VERSION "haltech-v2.35.0-subset"

NS_ :

BS_:

BU_: ECU GAUGES

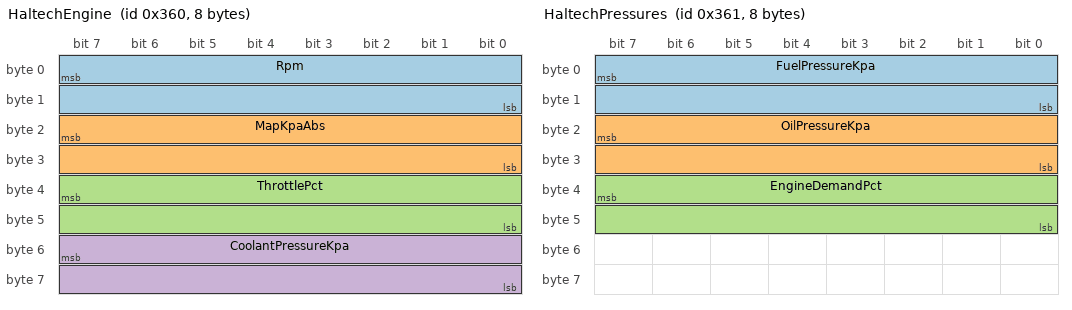
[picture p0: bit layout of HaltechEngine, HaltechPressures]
BO_ 864 HaltechEngine: 8 ECU
 SG_ Rpm : 7|16@0+ (1.0,0.0) [0.0|20000.0] "rpm" GAUGES
 SG_ MapKpaAbs : 23|16@0+ (0.1,0.0) [0.0|1000.0] "kPa" GAUGES
 SG_ ThrottlePct : 39|16@0+ (0.1,0.0) [0.0|100.0] "%" GAUGES
 SG_ CoolantPressureKpa : 55|16@0+ (0.1,-101.3) [-101.3|1000.0] "kPa" GAUGES

BO_ 865 HaltechPressures: 8 ECU
 SG_ FuelPressureKpa : 7|16@0+ (0.1,-101.3) [-101.3|1000.0] "kPa" GAUGES
 SG_ OilPressureKpa : 23|16@0+ (0.1,-101.3) [-101.3|1000.0] "kPa" GAUGES
 SG_ EngineDemandPct : 39|16@0+ (0.1,0.0) [0.0|400.0] "%" GAUGES

BO_ 880 HaltechSpeed: 8 ECU
 SG_ VehicleSpeedKph : 7|16@0+ (0.1,0.0) [0.0|400.0] "km/h" GAUGES

BO_ 882 HaltechBattery: 8 ECU
 SG_ BatteryV : 7|16@0+ (0.1,0.0) [0.0|30.0] "V" GAUGES

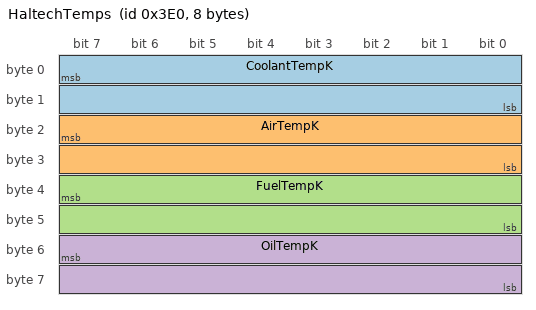
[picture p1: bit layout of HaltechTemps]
BO_ 992 HaltechTemps: 8 ECU
 SG_ CoolantTempK : 7|16@0+ (0.1,0.0) [0.0|500.0] "K" GAUGES
 SG_ AirTempK : 23|16@0+ (0.1,0.0) [0.0|500.0] "K" GAUGES
 SG_ FuelTempK : 39|16@0+ (0.1,0.0) [0.0|500.0] "K" GAUGES
 SG_ OilTempK : 55|16@0+ (0.1,0.0) [0.0|500.0] "K" GAUGES

BO_ 994 HaltechFuelLevel: 8 ECU
 SG_ FuelLevelL : 7|16@0+ (0.1,0.0) [0.0|500.0] "L" GAUGES

CM_ BO_ 864 "RPM, manifold pressure (absolute), throttle, coolant pressure.";
CM_ BO_ 865 "Fuel pressure, oil pressure (absolute minus 101.3), demand.";
CM_ BO_ 880 "Vehicle speed (only sent if the ECU's speed input is set up).";
CM_ BO_ 882 "Battery voltage.";
CM_ BO_ 992 "Temperatures in kelvin (x/10).";
CM_ BO_ 994 "Fuel level in litres (x/10).";

BA_DEF_ BO_ "GenMsgCycleTime" INT 0 65535;
BA_DEF_DEF_ "GenMsgCycleTime" 0;
BA_ "GenMsgCycleTime" BO_ 864 20;
BA_ "GenMsgCycleTime" BO_ 865 20;
BA_ "GenMsgCycleTime" BO_ 880 50;
BA_ "GenMsgCycleTime" BO_ 882 100;
BA_ "GenMsgCycleTime" BO_ 992 200;
BA_ "GenMsgCycleTime" BO_ 994 200;
